# MAIN_CTRL_MMR_MAIN_CTRL_MMR_CFG0_00100000h register map
Vendor: Texas Instruments
Peripheral module from a debugger description file (folder AM275x).
Registers are 32-bit, read-write, reset 0x0 unless marked. A register's access mark holds for its fields unless they carry their own. Offsets are as the file gives them; lines under a group give offsets from that group; [hi:lo] are bit positions; {n}, {i} and the like mark numbered series; 'fields as' and 'values as' point back to an identical list; <NAME> marks a mode.

## main_ctrl_mmr_CFG0 (part 1 of 3)
{0x84F0+4i} MAIN_CTRL_MMRCFG0_ASRC1_TXSYNC{i}_SEL (i=0..3) — Selects the source signal for the ASRC1 TXSYNC{i} frame sync input
  [4:0] ASRC1_TXSYNC{i}_SEL_SYNC_SEL — TXSYNC source signalField values (others are reserved):5'b00000 - McASP0 AFSX Pin Input5'b00001 - McASP1 AFSX Pin Input5'b00010 - McASP2 AFSX Pin Input5'b00011 - McASP3 AFSX Pin Input5'b00100 - McASP4 AFSX Pin Input5'b00101 - '0' - Reserved5'b00110 - '0' - Reserved5'b00111 - '0' - Reserved5'b01000 - McASP0 AFSX Pin Input5'b01001 - McASP1 AFSX Pin Input5'b01010 - McASP2 AFSX Pin Input5'b01011 - McASP3 AFSX Pin Input5'b01100 - McASP4 AFSX Pin Input5'b01101 - '0' - Reserved5'b01110 - '0' - Reserved5'b01111 - '0' - Reserved5'b10000 - AUDIO_EXT_REFCLK0 Pin input5'b10001 - AUDIO_EXT_REFCLK1 Pin input5'b10010 - AUDIO_EXT_REFCLK2 Pin input5'b10011 - '0' - Reserved5'b10100 - ADC0_CLK5'b10101 - MLB_IO_CLK5'b10110 - MAIN_PLL4_HSDIV3_CLKOUT5'b10111 - '0' - Reserved5'b11000 - MCU_EXT_REFCLK0 Pin5'b11001 - EXT_REFCLK1 Pin5'b11010 - CPSW_CPTS_GENF05'b11011 - CPSW_CPTS_GENF15'b11100 - '0' - Reserved5'b11101 - '0' - Reserved5'b11110 - '0' - Reserved5'b11111 - '0' - Reserved Reset Source: mod_g_rst_n
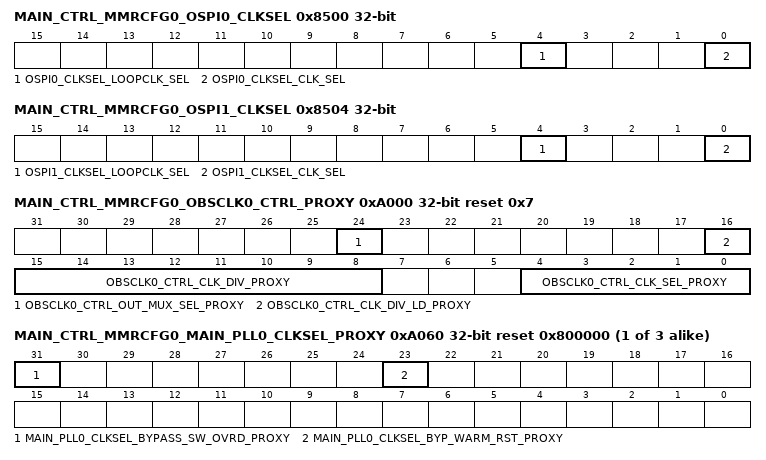
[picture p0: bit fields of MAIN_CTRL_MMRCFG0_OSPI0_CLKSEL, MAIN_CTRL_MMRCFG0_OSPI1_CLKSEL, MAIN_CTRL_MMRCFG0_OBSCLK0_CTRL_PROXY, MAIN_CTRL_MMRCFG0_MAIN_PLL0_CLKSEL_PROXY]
0x8500 MAIN_CTRL_MMRCFG0_OSPI0_CLKSEL — Controls the OSPI loopback clock source
  [4] OSPI0_CLKSEL_LOOPCLK_SEL — OSPI0 Loopback clock sourceField values (others are reserved):1'b0 - Board Level Loopback1'b1 - Internal Loopback Reset Source: mod_g_rst_n
  [0] OSPI0_CLKSEL_CLK_SEL — OSPI0 reference clock selectionField values (others are reserved):1'b0 - MAIN_PLL0_HSDIV1_CLKOUT1'b1 - MAIN_PLL1_HSDIV5_CLKOUT Reset Source: mod_g_rst_n
0x8504 MAIN_CTRL_MMRCFG0_OSPI1_CLKSEL — Controls the OSPI loopback clock source
  [4] OSPI1_CLKSEL_LOOPCLK_SEL — OSPI1 Loopback clock sourceField values (others are reserved):1'b0 - Board Level Loopback1'b1 - Internal Loopback Reset Source: mod_g_rst_n
  [0] OSPI1_CLKSEL_CLK_SEL — OSPI1 reference clock selectionField values (others are reserved):1'b0 - MAIN_PLL0_HSDIV1_CLKOUT1'b1 - MAIN_PLL1_HSDIV5_CLKOUT Reset Source: mod_g_rst_n
0x8510 MAIN_CTRL_MMRCFG0_ADC0_CLKSEL — Controls the functional clock source for the ADC0
  [1:0] ADC0_CLKSEL_CLK_SEL — Selects the sampling clock source for ADC0Field values (others are reserved):2'b00 - HFOSC0_CLKOUT2'b01 - HFOSC1_CLKOUT2'b10 - MAIN_PLL1_HSDIV4_CLKOUT2'b11 - EXT_REFCLK1 (Pin) Reset Source: mod_g_rst_n
0x8580 MAIN_CTRL_MMRCFG0_R5SS0_CLKSEL — Controls Main R5 Subsystem 0 clocking
  [0] R5SS0_CLKSEL_CORE_CLK_SEL — Selects R5SS core and interface clock rateField values (others are reserved):1'b0 - MAIN_PLL14_HSDIV_CLKOUT1'b1 - MAIN_PLL14_HSDIV_CLKOUT / 2 (half speed) Reset Source: mod_g_rst_n
0x8584 MAIN_CTRL_MMRCFG0_R5SS1_CLKSEL — Controls Main R5 Subsystem 1 clocking
  [0] R5SS1_CLKSEL_CORE_CLK_SEL — Selects R5SS core and interface clock rateField values (others are reserved):1'b0 - MAIN_PLL14_HSDIV_CLKOUT1'b1 - MAIN_PLL14_HSDIV_CLKOUT / 2 (half speed) Reset Source: mod_g_rst_n
0x9104 MAIN_CTRL_MMRCFG0_CLAIMREG_P2_R1_READONLY ro
  [31:0] CLAIMREG_P2_R1_READONLY — Claim bits for Partition 2 Reset Source: mod_g_rst_n
0x9110 MAIN_CTRL_MMRCFG0_CLAIMREG_P2_R4_READONLY ro
  [31:0] CLAIMREG_P2_R4_READONLY — Claim bits for Partition 2 Reset Source: mod_g_rst_n
0x9114 MAIN_CTRL_MMRCFG0_CLAIMREG_P2_R5_READONLY ro
  [31:0] CLAIMREG_P2_R5_READONLY — Claim bits for Partition 2 Reset Source: mod_g_rst_n
0x911C MAIN_CTRL_MMRCFG0_CLAIMREG_P2_R7_READONLY ro
  [31:0] CLAIMREG_P2_R7_READONLY — Claim bits for Partition 2 Reset Source: mod_g_rst_n
0x9124 MAIN_CTRL_MMRCFG0_CLAIMREG_P2_R9_READONLY ro
  [31:0] CLAIMREG_P2_R9_READONLY — Claim bits for Partition 2 Reset Source: mod_g_rst_n
0x9128 MAIN_CTRL_MMRCFG0_CLAIMREG_P2_R10_READONLY ro
  [31:0] CLAIMREG_P2_R10_READONLY — Claim bits for Partition 2 Reset Source: mod_g_rst_n
0xA000 MAIN_CTRL_MMRCFG0_OBSCLK0_CTRL_PROXY reset 0x7 — This register controls which internal clock is made observable on the OBSCLK0/1 output pins
  [24] OBSCLK0_CTRL_OUT_MUX_SEL_PROXY — OBSCLK pin output mux selection. PLL4_REFCLK is the direct output from either HFOSC0 or HFOSC1.Field values (others are reserved):1'b0 - Selects the output of the CLK_DIV_OUT clock mux1'b1 - Select PLL4_REFCLK (clk_sel value must be 5'b11111) Reset Source: mod_por_rst_n
  [16] OBSCLK0_CTRL_CLK_DIV_LD_PROXY — Load divisor value from clk_div field, when the bit is toggled from 0 to 1. Field values (others are reserved):1'b0 - READY1'b1 - LOAD Reset Source: mod_por_rst_n
  [15:8] OBSCLK0_CTRL_CLK_DIV_PROXY — OBSCLK0 output divider. Sets divider to divide by clkdiv + 1. Divide by 1 to 256 are supported. After Writing to this field, the clk_div_ld field must be toggled. Reset Source: mod_por_rst_n
  [4:0] OBSCLK0_CTRL_CLK_SEL_PROXY — OBSCLK0 clock source selection.Selects the source of the clock to be divided by the OBSCLK0 divider.Field values (others are reserved):5'b00000 - MAIN_PLL0_HSDIV0_CLKOUT5'b00001 - MAIN_PLL1_HSDIV0_CLKOUT5'b00010 - MAIN_PLL2_HSDIV0_CLKOUT5'b00011 - MAIN_PLL4_HSDIV0_CLKOUT5'b00100 - MAIN_PLL14_HSDIV0_CLKOUT5'b00101 - CLK_12M_RC5'b00110 - HFOSC0_CLKOUT_32K5'b00111 - PLLCTRL_OBSCLK5'b01000 - HFOSC0_CLKOUT5'b01001 - CLK_32K_RC5'b01010 - CPSW0_CPTS_GENF05'b01011 - CPSW0_CPTS_GENF15'b01100 - MCU_PLL0_HSDIV0_CLKOUT5'b01101 - MAIN_PLL15_HSDIV0_CLKOUTundefined - undefinedundefined - undefinedundefined - undefined5'b10000 - MAIN_SYSCLK05'b10001 - DEVICE_CLKOUT_32Kundefined - undefined5'b10011 - C7XV_CLK_DIV4undefined - undefinedundefined - undefined5'b11111 - OFF (Must Select this option when out_mux_sel is set to PLL4_REFCLK) Reset Source: mod_por_rst_n
0xA010 MAIN_CTRL_MMRCFG0_CLKOUT_CTRL_PROXY — Enables and selects clock source of CPSW CLKOUT pin
  [0] CLKOUT_CTRL_CLK_SEL_PROXY — Selects CLKOUT clock sourceField values (others are reserved):1'b0 - MAIN_PLL2_HSDIV1_CLKOUT / 51'b1 - MAIN_PLL2_HSDIV1_CLKOUT / 10 Reset Source: mod_g_rst_n
{0xA060+4i} MAIN_CTRL_MMRCFG0_MAIN_PLL{i}_CLKSEL_PROXY reset 0x800000 (i=0..2) — Controls the clock source for MAIN voltage domain PLL{i}
  [31] MAIN_PLL{i}_CLKSEL_BYPASS_SW_OVRD_PROXY — PLL Bypass warm reset software overrideWhen set, enables software control of exit from bypass mode on a main_reset_z for MAIN PLL{i}. This bit must not be set until after the corresponding byp_warm_rst bit has been cleared or the PLL will immediately enter bypass mode.Field values (others are reserved):1'b0 - Disable1'b1 - Enable Reset Source: sys_por_rst_n
  [23] MAIN_PLL{i}_CLKSEL_BYP_WARM_RST_PROXY — PLL bypass mode after warm reset.This bit is only valid when bypass_sw_ovrd is set to 1'b1 to enable bypass software override.This bit is set (1'b1) when a MAIN warm reset occurs and will keep MAIN PLL{i} in bypass mode after reset exit until cleared by software.Field values (others are reserved):1'b0 - EXIT_BYPASS1'b1 - MAINTAIN_BYPASS Reset Source: main_chip1_rst_n
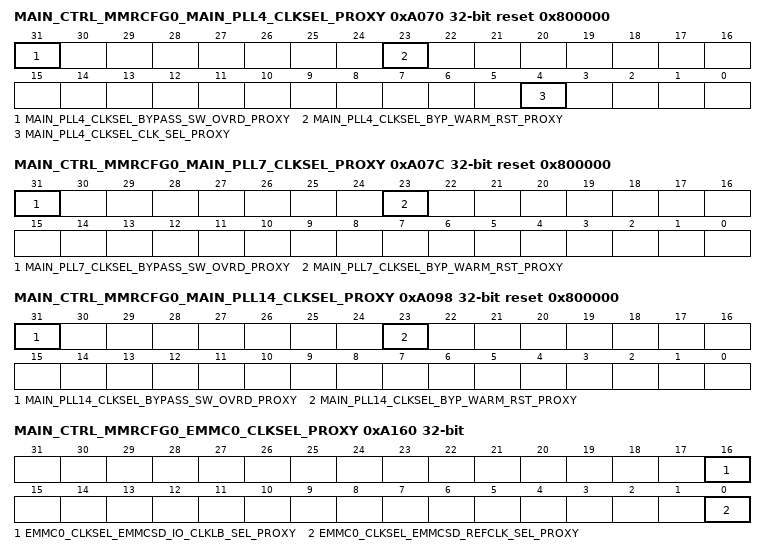
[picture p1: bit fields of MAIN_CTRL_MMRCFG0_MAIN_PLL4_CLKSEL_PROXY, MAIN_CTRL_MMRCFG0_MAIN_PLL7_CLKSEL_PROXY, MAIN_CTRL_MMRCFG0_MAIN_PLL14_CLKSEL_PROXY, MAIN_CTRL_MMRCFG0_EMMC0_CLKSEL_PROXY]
0xA070 MAIN_CTRL_MMRCFG0_MAIN_PLL4_CLKSEL_PROXY reset 0x800000 — Controls the clock source for MAIN voltage domain PLL4
  [31] MAIN_PLL4_CLKSEL_BYPASS_SW_OVRD_PROXY — PLL Bypass warm reset software overrideWhen set, enables software control of exit from bypass mode on a main_reset_z for MAIN PLL4. This bit must not be set until after the corresponding byp_warm_rst bit has been cleared or the PLL will immediately enter bypass mode.Field values (others are reserved):1'b0 - Disable1'b1 - Enable Reset Source: sys_por_rst_n
  [23] MAIN_PLL4_CLKSEL_BYP_WARM_RST_PROXY — PLL bypass mode after warm reset.This bit is only valid when bypass_sw_ovrd is set to 1'b1 to enable bypass software override.This bit is set (1'b1) when a MAIN warm reset occurs and will keep MAIN PLL4 in bypass mode after reset exit until cleared by software.Field values (others are reserved):1'b0 - EXIT_BYPASS1'b1 - MAINTAIN_BYPASS Reset Source: main_chip1_rst_n
  [4] MAIN_PLL4_CLKSEL_CLK_SEL_PROXY — Selects the clock source for MAIN PLL4 1'b0 - Use HFOSC0_CLKOUT 1'b1 - Use HFOSC1_CLKOUT Reset Source: mod_g_rst_n
0xA07C MAIN_CTRL_MMRCFG0_MAIN_PLL7_CLKSEL_PROXY reset 0x800000 — Controls the clock source for MAIN voltage domain PLL7
  [31] MAIN_PLL7_CLKSEL_BYPASS_SW_OVRD_PROXY — PLL Bypass warm reset software overrideWhen set, enables software control of exit from bypass mode on a main_reset_z for MAIN PLL7. This bit must not be set until after the corresponding byp_warm_rst bit has been cleared or the PLL will immediately enter bypass mode.Field values (others are reserved):1'b0 - Disable1'b1 - Enable Reset Source: sys_por_rst_n
  [23] MAIN_PLL7_CLKSEL_BYP_WARM_RST_PROXY — PLL bypass mode after warm reset.This bit is only valid when bypass_sw_ovrd is set to 1'b1 to enable bypass software override.This bit is set (1'b1) when a MAIN warm reset occurs and will keep MAIN PLL7 in bypass mode after reset exit until cleared by software.Field values (others are reserved):1'b0 - EXIT_BYPASS1'b1 - MAINTAIN_BYPASS Reset Source: main_chip1_rst_n
0xA098 MAIN_CTRL_MMRCFG0_MAIN_PLL14_CLKSEL_PROXY reset 0x800000 — Controls the clock source for MAIN voltage domain PLL14
  [31] MAIN_PLL14_CLKSEL_BYPASS_SW_OVRD_PROXY — PLL Bypass warm reset software overrideWhen set, enables software control of exit from bypass mode on a main_reset_z for MAIN PLL14. This bit must not be set until after the corresponding byp_warm_rst bit has been cleared or the PLL will immediately enter bypass mode.Field values (others are reserved):1'b0 - Disable1'b1 - Enable Reset Source: sys_por_rst_n
  [23] MAIN_PLL14_CLKSEL_BYP_WARM_RST_PROXY — PLL bypass mode after warm reset.This bit is only valid when bypass_sw_ovrd is set to 1'b1 to enable bypass software override.This bit is set (1'b1) when a MAIN warm reset occurs and will keep MAIN PLL14 in bypass mode after reset exit until cleared by software.Field values (others are reserved):1'b0 - EXIT_BYPASS1'b1 - MAINTAIN_BYPASS Reset Source: main_chip1_rst_n
0xA140 MAIN_CTRL_MMRCFG0_CPSW_CLKSEL_PROXY reset 0x7 — Selects the CP Switch clock sources
  [2:0] CPSW_CLKSEL_CPTS_CLKSEL_PROXY — Selects the clock source for the CPSW Ethernet switch Common Platform Time Stamp moduleField values (others are reserved):3'b000 - MAIN_PLL2_HSDIV5_CLKOUT3'b001 - MAIN_PLL0_HSDIV6_CLKOUT3'b010 - CP_GEMAC_CPTS0_RFT_CLK (Pin)3'b011 - Reserved3'b100 - MCU_EXT_REFCLK0 (Pin)3'b101 - EXT_REFCLK1 (Pin)3'b110 - SERDES0_IP1_LN0_TXMCLKundefined - undefined3'b111 - MAIN_SYSCLK0 Reset Source: mod_por_rst_n
0xA160 MAIN_CTRL_MMRCFG0_EMMC0_CLKSEL_PROXY — Selects the functional clock source for 8-bit eMMC0
  [16] EMMC0_CLKSEL_EMMCSD_IO_CLKLB_SEL_PROXY — Selects IO Pad Loopback for the MMC ModuleField values (others are reserved):1'b0 - Loopback from Unbonded Pad MMCSD0_CLKLB1'b1 - Loopback from IO Pin MMCSD0_CLK Reset Source: mod_g_rst_n
  [0] EMMC0_CLKSEL_EMMCSD_REFCLK_SEL_PROXY — Selects the functional clock for the MMC ModuleField values (others are reserved):1'b0 - MAIN_PLL0_HSDIV5_CLKOUT1'b1 - MAIN_PLL2_HSDIV2_CLKOUT Reset Source: mod_g_rst_n
{0xA1B0+4i} MAIN_CTRL_MMRCFG0_TIMER{i}_CLKSEL_PROXY (i=0..15) — Timer{i} functional clock selection control
  [3:0] TIMER{i}_CLKSEL_CLK_SEL_PROXY — Timer functional clock input select control.Field values (others are reserved):4'b0000 - HFOSC0_CLKOUT4'b0001 - DEVICE_CLKOUT_32K4'b0010 - MAIN_PLL0_HSDIV7_CLKOUT4'b0011 - CLK_12M_RC4'b0100 - MCU_EXT_REFCLK0 (Pin)4'b0101 - EXT_REFCLK1 (Pin)4'b0110 - Reserved4'b0111 - CP_GEMAC_CPTS0_RFT_CLK (Pin)4'b1000 - MAIN_PLL1_HSDIV3_CLKOUT4'b1001 - MAIN_PLL2_HSDIV6_CLKOUT4'b1010 - CPSW0_CPTS_GENF04'b1011 - CPSW0_CPTS_GENF14'b1100 - Reserved Reset Source: sys_por_rst_n
{0xA200+4i} MAIN_CTRL_MMRCFG0_SPI{i}_CLKSEL_PROXY (i=0..4) — SPI{i} clock control
  [16] SPI{i}_CLKSEL_MSTR_LB_CLKSEL_PROXY — Controller mode receive capture clock loopback selectionField values (others are reserved):1'b0 - INTERNAL_LOOPBACK1'b1 - EXTERNAL_LOOPBACK Reset Source: mod_g_rst_n
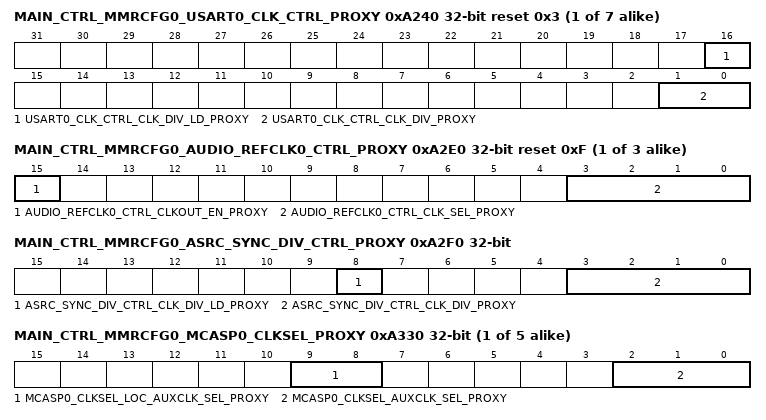
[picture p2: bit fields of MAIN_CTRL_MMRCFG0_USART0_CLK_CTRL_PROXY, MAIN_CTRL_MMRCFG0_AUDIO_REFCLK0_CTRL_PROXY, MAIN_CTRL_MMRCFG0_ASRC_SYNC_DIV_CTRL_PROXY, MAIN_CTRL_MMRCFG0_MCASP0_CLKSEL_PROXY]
{0xA240+4i} MAIN_CTRL_MMRCFG0_USART{i}_CLK_CTRL_PROXY reset 0x3 (i=0..6) — Selects the clock divider of the USART{i} functional clock
  [16] USART{i}_CLK_CTRL_CLK_DIV_LD_PROXY — Load the output divider valueWriting 1 to this bit will generate a load pulse to load the USART{i} clock programmable divider value. This bit can be cleared but must not be set in the same write cycle in which the clk_div value is changed. Field values (others are reserved):1'b0 - READY1'b1 - LOAD Reset Source: mod_g_rst_n
  [1:0] USART{i}_CLK_CTRL_CLK_DIV_PROXY — Selects the clock divider value. Supports divide values of 1 to 4 Default is /4. To load the new divider value the clk_div_ld bit must be cleared and then set to 1.Field values (others are reserved):2'b00 - Divide by 12'b01 - Divide by 22'b10 - Divide by 32'b11 - Divide by 4 Reset Source: mod_g_rst_n
{0xA280+4i} MAIN_CTRL_MMRCFG0_USART{i}_CLKSEL_PROXY (i=0..6) — Selects the clock source for USART{i} functional clock
  [0] USART{i}_CLKSEL_CLK_SEL_PROXY — Selects the clock source for UART{i}:Field values (others are reserved):1'b0 - MAIN_PLL1_HSDIV0_CLKOUT Divider Output (See USART{i}_CLK_CTRL)1'b1 - MAIN_PLL1_HSDIV1_CLKOUT Reset Source: mod_g_rst_n
0xA2B0 MAIN_CTRL_MMRCFG0_ATL_CLKSEL_PROXY — Selects the source of ATL PCLK which drives ATL Measurement and Adjustment Logic
  [2:0] ATL_CLKSEL_PCLK_SEL_PROXY — Selects the PCLK clock sourceField values (others are reserved):3'b000 - MAIN_PLL2_HSDIV8_CLKOUT3'b001 - MAIN_PLL1_HSDIV6_CLKOUT3'b010 - MAIN_PLL2_HSDIV0_CLKOUT3'b011 - MAIN_PLL4_HSDIV1_CLKOUT3'b100 - MAIN_PLL0_HSDIV7_CLKOUT3'b101 - MCU_EXT_REFCLK0 (Pin)3'b110 - EXT_REFCLK1 (Pin) Reset Source: mod_g_rst_n
{0xA2C0+4i} MAIN_CTRL_MMRCFG0_ATL_BWS{i}_SEL_PROXY (i=0..3) — Selects the word clock for the ATL channel{i} Baseband Stream
  [3:0] ATL_BWS{i}_SEL_WD_SEL_PROXY — BWS source signalField values (others are reserved):4'b0000 - MCASP0_AFSR_IN4'b0001 - MCASP1_AFSR_IN4'b0010 - MCASP2_AFSR_IN4'b0011 - MCASP3_AFSR_IN4'b0100 - MCASP4_AFSR_IN4'b0101 - MCASP0_AFSX_IN4'b0110 - MCASP1_AFSX_IN4'b0111 - MCASP2_AFSX_IN4'b1000 - MCASP3_AFSX_IN4'b1001 - MCASP4_AFSX_IN4'b1010 - AUDIO_EXT_REFCLK0_IN4'b1011 - AUDIO_EXT_REFCLK1_IN4'b1100 - AUDIO_EXT_REFCLK2_IN Reset Source: mod_g_rst_n
{0xA2D0+4i} MAIN_CTRL_MMRCFG0_ATL_AWS{i}_SEL_PROXY (i=0..3) — Selects the word clock for the ATL channel{i} Audio Stream
  [3:0] ATL_AWS{i}_SEL_WD_SEL_PROXY — AWS source signalField values (others are reserved):4'b0000 - MCASP0_AFSX_IN4'b0001 - MCASP1_AFSX_IN4'b0010 - MCASP2_AFSX_IN4'b0011 - MCASP3_AFSX_IN4'b0100 - MCASP4_AFSX_IN4'b0101 - MCASP0_AFSX_IN4'b0110 - MCASP1_AFSX_IN4'b0111 - MCASP2_AFSX_IN4'b1000 - MCASP3_AFSX_IN4'b1001 - MCASP4_AFSX_IN4'b1010 - AUDIO_EXT_REFCLK0_IN4'b1011 - AUDIO_EXT_REFCLK1_IN4'b1100 - AUDIO_EXT_REFCLK2_IN Reset Source: mod_g_rst_n
{0xA2E0+4i} MAIN_CTRL_MMRCFG0_AUDIO_REFCLK{i}_CTRL_PROXY reset 0xF (i=0..2) — Selects the clock source for the AUDIO_EXT_REFCLK0 output, and direction.
  [15] AUDIO_REFCLK{i}_CTRL_CLKOUT_EN_PROXY — AUDIO_REFCLK {i} output enableField values (others are reserved):1'b0 - INPUT1'b1 - OUTPUT Reset Source: mod_g_rst_n
  [3:0] AUDIO_REFCLK{i}_CTRL_CLK_SEL_PROXY — Selects the source of AUDIO_REFCLK{i}Field values (others are reserved):4'b0000 - MCASP0_AHCLKR4'b0001 - MCASP1_AHCLKR4'b0010 - MCASP2_AHCLKR4'b0011 - MCASP3_AHCLKR4'b0100 - MCASP4_AHCLKR4'b0101 - MCASP0_AHCLKX4'b0110 - MCASP1_AHCLKX4'b0111 - MCASP2_AHCLKX4'b1000 - MCASP3_AHCLKX4'b1001 - MCASP4_AHCLKX4'b1010 - ATCLK04'b1011 - ATCLK14'b1100 - ATCLK24'b1101 - ATCLK34'b1110 - MAIN_PLL1_HSDIV6_CLKOUTundefined - undefined4'b1111 - MAIN_PLL4_HSDIV0_CLKOUT Reset Source: mod_g_rst_n
0xA2F0 MAIN_CTRL_MMRCFG0_ASRC_SYNC_DIV_CTRL_PROXY — Selects additional divide value for the MAIN_PLL4 clock source to the ASRC RXSYNC and TXSYNC selection muxes
  [8] ASRC_SYNC_DIV_CTRL_CLK_DIV_LD_PROXY — Load the divider valueWriting 1 to this bit will generate a load pulse to load the clk_div divider value. This bit can be cleared but must not be set in the same write cycle in which the clk_div value is changed. Field values (others are reserved):1'b0 - READY1'b1 - LOAD Reset Source: mod_g_rst_n
  [3:0] ASRC_SYNC_DIV_CTRL_CLK_DIV_PROXY — ASRC Sync divider valueDivides MAIN_PLL4_HSDIV_CLKOUT3 by clkdiv+1. Supports divide by 1 to 16 (default to 1). To load the new divider value the clk_div_ld bit must be cleared and then set to 1. Reset Source: mod_g_rst_n
{0xA330+4i} MAIN_CTRL_MMRCFG0_MCASP{i}_CLKSEL_PROXY (i=0..4) — Selects the functional clock source for McASP{i}
  [9:8] MCASP{i}_CLKSEL_LOC_AUXCLK_SEL_PROXY — Selects the local clock source to use for McASP{i} AUXCLKField values (others are reserved):2'b00 - PLL4_REF_CLK (as selected by MAIN_PLL4_CLKSEL_clk_sel)2'b01 - PLL4_REF_CLK / 2 (as selected by MAIN_PLL4_CLKSEL_clk_sel)2'b10 - MAIN_PLL4_HSDIV0_CLKOUT Reset Source: mod_g_rst_n
  [2:0] MCASP{i}_CLKSEL_AUXCLK_SEL_PROXY — Selects the system AUXCLK input source for McASP{i}Field values (others are reserved):3'b000 - MAIN_PLL2_HSDIV8_CLKOUT3'b001 - MAIN_PLL1_HSDIV6_CLKOUT3'b011 - AUDIO_EXT_REFCLK0 (Pin)3'b100 - AUDIO_EXT_REFCLK1 (Pin)3'b101 - AUDIO_EXT_REFCLK2 (Pin)3'b110 - ATCLK03'b111 - ATCLK1 Reset Source: mod_g_rst_n
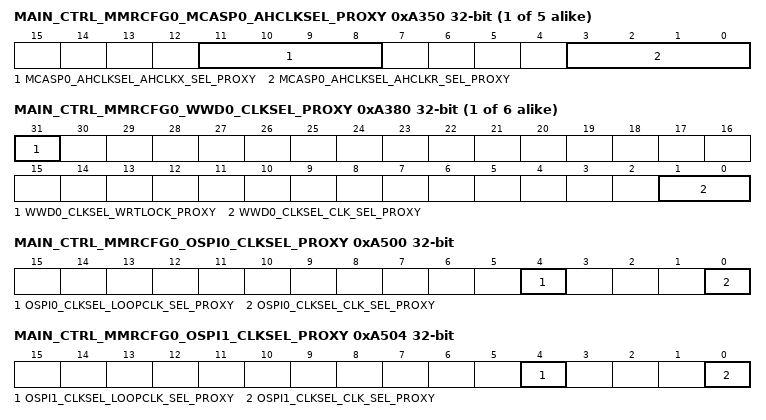
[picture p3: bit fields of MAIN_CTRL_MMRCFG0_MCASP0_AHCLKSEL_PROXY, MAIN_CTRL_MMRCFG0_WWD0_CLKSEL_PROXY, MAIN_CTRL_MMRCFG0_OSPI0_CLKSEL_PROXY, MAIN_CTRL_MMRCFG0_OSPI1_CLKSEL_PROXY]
{0xA350+4i} MAIN_CTRL_MMRCFG0_MCASP{i}_AHCLKSEL_PROXY (i=0..4) — Selects the AHCLKX and AHCLKR clock source for McASP{i}
  [11:8] MCASP{i}_AHCLKSEL_AHCLKX_SEL_PROXY — Selects the AHCLKX input source for McASP{i}Field values (others are reserved):4'b0000 - EXT_REFCLK1 (Pin)4'b0001 - HFOSC0_CLKOUT4'b0010 - AUDIO_EXT_REFCLK0 (Pin)4'b0011 - AUDIO_EXT_REFCLK1 (Pin)4'b0100 - AUDIO_EXT_REFCLK2 (Pin)undefined - undefined4'b0110 - MLB_IO_CLKundefined - undefined4'b1000 - ATCLK04'b1001 - ATCLK14'b1010 - ATCLK24'b1011 - ATCLK34'b1100 - CPSW CPTS GENF04'b1101 - CPSW CPTS GENF0 Reset Source: mod_g_rst_n
  [3:0] MCASP{i}_AHCLKSEL_AHCLKR_SEL_PROXY — Selects the AHCLKR input source for McASP{i}Field values (others are reserved):4'b0000 - EXT_REFCLK1 (Pin)4'b0001 - HFOSC0_CLKOUT4'b0010 - AUDIO_EXT_REFCLK0 (Pin)4'b0011 - AUDIO_EXT_REFCLK1 (Pin)4'b0100 - AUDIO_EXT_REFCLK2 (Pin)undefined - undefined4'b0110 - MLB_IO_CLKundefined - undefined4'b1000 - ATCLK04'b1001 - ATCLK14'b1010 - ATCLK24'b1011 - ATCLK34'b1100 - CPSW CPTS GENF04'b1101 - CPSW CPTS GENF0 Reset Source: mod_g_rst_n
{0xA380+4i} MAIN_CTRL_MMRCFG0_WWD{i}_CLKSEL_PROXY (i=0..5) — Windowed Watchdog WWD{i} functional clock selection control
  [31] WWD{i}_CLKSEL_WRTLOCK_PROXY — When set, locks WWD{i}_CLKSEL from further writes until the next module reset.Field values (others are reserved):1'b0 - UNLOCKED1'b1 - LOCKED Reset Source: mod_g_rst_n
  [1:0] WWD{i}_CLKSEL_CLK_SEL_PROXY — Windowed watchdog timer functional clock input select mux controlField values (others are reserved):2'b00 - HFOSC0_CLKOUT2'b01 - DEVICE_CLKOUT_32K2'b10 - CLK_12M_RC2'b11 - CLK_32K Reset Source: mod_g_rst_n
{0xA3E0+4i} MAIN_CTRL_MMRCFG0_MCASP{i}_GF_CLK_SEL_PROXY (i=0..4) — Performs glitchfree selection of the McASP{i} functional clock
  [16] MCASP{i}_GF_CLK_SEL_AUXCLK_GF_SEL_PROXY — Provides glitch-free switching between the local and system AUXCLK source for McASP{i} based on MCASP{i}_CLKSEL loc_auxclk_sel and auxclk_sel settings.Field values (others are reserved):1'b0 - Use local AUXCLK source (as selected by loc_auxclk_sel bitfield)1'b1 - Use system AUXCLK source (as selected by auxsel_sel bitfield) Reset Source: mod_g_rst_n
{0xA480+4i} MAIN_CTRL_MMRCFG0_MCAN{i}_CLKSEL_PROXY (i=0..4) — Controls the functional clock source for MCAN{i}
  [1:0] MCAN{i}_CLKSEL_CLK_SEL_PROXY — MCAN functional clock selectionField values (others are reserved):2'b00 - MAIN_PLL0_HSDIV4_CLKOUT2'b01 - MCU_EXT_REFCLK0 (Pin)2'b10 - EXT_REFCLK1 (Pin)2'b11 - HFOSC0_CLKOUT Reset Source: sys_por_rst_n
{0xA4C0+4i} MAIN_CTRL_MMRCFG0_ASRC0_RXSYNC{i}_SEL_PROXY (i=0..3) — Selects the source signal for the ASRC0 RXSYNC{i} frame sync input
  [4:0] ASRC0_RXSYNC{i}_SEL_SYNC_SEL_PROXY — RXSYNC source signalField values (others are reserved):5'b00000 - McASP0 AFSR Pin Input5'b00001 - McASP1 AFSR Pin Input5'b00010 - McASP2 AFSR Pin Input5'b00011 - McASP3 AFSR Pin Input5'b00100 - McASP4 AFSR Pin Input5'b00101 - '0' - Reserved5'b00110 - '0' - Reserved5'b00111 - '0' - Reserved5'b01000 - McASP0 AFSX Pin Input5'b01001 - McASP1 AFSX Pin Input5'b01010 - McASP2 AFSX Pin Input5'b01011 - McASP3 AFSX Pin Input5'b01100 - McASP4 AFSX Pin Input5'b01101 - '0' - Reserved5'b01110 - '0' - Reserved5'b01111 - '0' - Reserved5'b10000 - AUDIO_EXT_REFCLK0 Pin input5'b10001 - AUDIO_EXT_REFCLK1 Pin input5'b10010 - AUDIO_EXT_REFCLK2 Pin input5'b10011 - '0' - Reserved5'b10100 - ADC0_CLK5'b10101 - MLB_IO_CLK5'b10110 - MAIN_PLL4_HSDIV3_CLKOUT5'b10111 - '0' - Reserved5'b11000 - MCU_EXT_REFCLK0 Pin5'b11001 - EXT_REFCLK1 Pin5'b11010 - CPSW_CPTS_GENF05'b11011 - CPSW_CPTS_GENF15'b11100 - '0' - Reserved5'b11101 - '0' - Reserved5'b11110 - '0' - Reserved5'b11111 - '0' - Reserved Reset Source: mod_g_rst_n
{0xA4D0+4i} MAIN_CTRL_MMRCFG0_ASRC1_RXSYNC{i}_SEL_PROXY (i=0..3) — Selects the source signal for the ASRC1 RXSYNC{i} frame sync input
  [4:0] ASRC1_RXSYNC{i}_SEL_SYNC_SEL_PROXY — RXSYNC source signalField values (others are reserved):5'b00000 - McASP0 AFSR Pin Input5'b00001 - McASP1 AFSR Pin Input5'b00010 - McASP2 AFSR Pin Input5'b00011 - McASP3 AFSR Pin Input5'b00100 - McASP4 AFSR Pin Input5'b00101 - '0' - Reserved5'b00110 - '0' - Reserved5'b00111 - '0' - Reserved5'b01000 - McASP0 AFSX Pin Input5'b01001 - McASP1 AFSX Pin Input5'b01010 - McASP2 AFSX Pin Input5'b01011 - McASP3 AFSX Pin Input5'b01100 - McASP4 AFSX Pin Input5'b01101 - '0' - Reserved5'b01110 - '0' - Reserved5'b01111 - '0' - Reserved5'b10000 - AUDIO_EXT_REFCLK0 Pin input5'b10001 - AUDIO_EXT_REFCLK1 Pin input5'b10010 - AUDIO_EXT_REFCLK2 Pin input5'b10011 - '0' - Reserved5'b10100 - ADC0_CLK5'b10101 - MLB_IO_CLK5'b10110 - MAIN_PLL4_HSDIV3_CLKOUT5'b10111 - '0' - Reserved5'b11000 - MCU_EXT_REFCLK0 Pin5'b11001 - EXT_REFCLK1 Pin5'b11010 - CPSW_CPTS_GENF05'b11011 - CPSW_CPTS_GENF15'b11100 - '0' - Reserved5'b11101 - '0' - Reserved5'b11110 - '0' - Reserved5'b11111 - '0' - Reserved Reset Source: mod_g_rst_n
{0xA4E0+4i} MAIN_CTRL_MMRCFG0_ASRC0_TXSYNC{i}_SEL_PROXY (i=0..3) — Selects the source signal for the ASRC0 TXSYNC{i} frame sync input
  [4:0] ASRC0_TXSYNC{i}_SEL_SYNC_SEL_PROXY — TXSYNC source signalField values (others are reserved):5'b00000 - McASP0 AFSX Pin Input5'b00001 - McASP1 AFSX Pin Input5'b00010 - McASP2 AFSX Pin Input5'b00011 - McASP3 AFSX Pin Input5'b00100 - McASP4 AFSX Pin Input5'b00101 - '0' - Reserved5'b00110 - '0' - Reserved5'b00111 - '0' - Reserved5'b01000 - McASP0 AFSX Pin Input5'b01001 - McASP1 AFSX Pin Input5'b01010 - McASP2 AFSX Pin Input5'b01011 - McASP3 AFSX Pin Input5'b01100 - McASP4 AFSX Pin Input5'b01101 - '0' - Reserved5'b01110 - '0' - Reserved5'b01111 - '0' - Reserved5'b10000 - AUDIO_EXT_REFCLK0 Pin input5'b10001 - AUDIO_EXT_REFCLK1 Pin input5'b10010 - AUDIO_EXT_REFCLK2 Pin input5'b10011 - '0' - Reserved5'b10100 - ADC0_CLK5'b10101 - MLB_IO_CLK5'b10110 - MAIN_PLL4_HSDIV3_CLKOUT5'b10111 - '0' - Reserved5'b11000 - MCU_EXT_REFCLK0 Pin5'b11001 - EXT_REFCLK1 Pin5'b11010 - CPSW_CPTS_GENF05'b11011 - CPSW_CPTS_GENF15'b11100 - '0' - Reserved5'b11101 - '0' - Reserved5'b11110 - '0' - Reserved5'b11111 - '0' - Reserved Reset Source: mod_g_rst_n
{0xA4F0+4i} MAIN_CTRL_MMRCFG0_ASRC1_TXSYNC{i}_SEL_PROXY (i=0..3) — Selects the source signal for the ASRC1 TXSYNC{i} frame sync input
  [4:0] ASRC1_TXSYNC{i}_SEL_SYNC_SEL_PROXY — TXSYNC source signalField values (others are reserved):5'b00000 - McASP0 AFSX Pin Input5'b00001 - McASP1 AFSX Pin Input5'b00010 - McASP2 AFSX Pin Input5'b00011 - McASP3 AFSX Pin Input5'b00100 - McASP4 AFSX Pin Input5'b00101 - '0' - Reserved5'b00110 - '0' - Reserved5'b00111 - '0' - Reserved5'b01000 - McASP0 AFSX Pin Input5'b01001 - McASP1 AFSX Pin Input5'b01010 - McASP2 AFSX Pin Input5'b01011 - McASP3 AFSX Pin Input5'b01100 - McASP4 AFSX Pin Input5'b01101 - '0' - Reserved5'b01110 - '0' - Reserved5'b01111 - '0' - Reserved5'b10000 - AUDIO_EXT_REFCLK0 Pin input5'b10001 - AUDIO_EXT_REFCLK1 Pin input5'b10010 - AUDIO_EXT_REFCLK2 Pin input5'b10011 - '0' - Reserved5'b10100 - ADC0_CLK5'b10101 - MLB_IO_CLK5'b10110 - MAIN_PLL4_HSDIV3_CLKOUT5'b10111 - '0' - Reserved5'b11000 - MCU_EXT_REFCLK0 Pin5'b11001 - EXT_REFCLK1 Pin5'b11010 - CPSW_CPTS_GENF05'b11011 - CPSW_CPTS_GENF15'b11100 - '0' - Reserved5'b11101 - '0' - Reserved5'b11110 - '0' - Reserved5'b11111 - '0' - Reserved Reset Source: mod_g_rst_n
0xA500 MAIN_CTRL_MMRCFG0_OSPI0_CLKSEL_PROXY — Controls the OSPI loopback clock source
  [4] OSPI0_CLKSEL_LOOPCLK_SEL_PROXY — OSPI0 Loopback clock sourceField values (others are reserved):1'b0 - Board Level Loopback1'b1 - Internal Loopback Reset Source: mod_g_rst_n
  [0] OSPI0_CLKSEL_CLK_SEL_PROXY — OSPI0 reference clock selectionField values (others are reserved):1'b0 - MAIN_PLL0_HSDIV1_CLKOUT1'b1 - MAIN_PLL1_HSDIV5_CLKOUT Reset Source: mod_g_rst_n
0xA504 MAIN_CTRL_MMRCFG0_OSPI1_CLKSEL_PROXY — Controls the OSPI loopback clock source
  [4] OSPI1_CLKSEL_LOOPCLK_SEL_PROXY — OSPI1 Loopback clock sourceField values (others are reserved):1'b0 - Board Level Loopback1'b1 - Internal Loopback Reset Source: mod_g_rst_n
  [0] OSPI1_CLKSEL_CLK_SEL_PROXY — OSPI1 reference clock selectionField values (others are reserved):1'b0 - MAIN_PLL0_HSDIV1_CLKOUT1'b1 - MAIN_PLL1_HSDIV5_CLKOUT Reset Source: mod_g_rst_n
0xA510 MAIN_CTRL_MMRCFG0_ADC0_CLKSEL_PROXY — Controls the functional clock source for the ADC0
  [1:0] ADC0_CLKSEL_CLK_SEL_PROXY — Selects the sampling clock source for ADC0Field values (others are reserved):2'b00 - HFOSC0_CLKOUT2'b01 - HFOSC1_CLKOUT2'b10 - MAIN_PLL1_HSDIV4_CLKOUT2'b11 - EXT_REFCLK1 (Pin) Reset Source: mod_g_rst_n
0xA580 MAIN_CTRL_MMRCFG0_R5SS0_CLKSEL_PROXY — Controls Main R5 Subsystem 0 clocking
  [0] R5SS0_CLKSEL_CORE_CLK_SEL_PROXY — Selects R5SS core and interface clock rateField values (others are reserved):1'b0 - MAIN_PLL14_HSDIV_CLKOUT1'b1 - MAIN_PLL14_HSDIV_CLKOUT / 2 (half speed) Reset Source: mod_g_rst_n
0xA584 MAIN_CTRL_MMRCFG0_R5SS1_CLKSEL_PROXY — Controls Main R5 Subsystem 1 clocking
  [0] R5SS1_CLKSEL_CORE_CLK_SEL_PROXY — Selects R5SS core and interface clock rateField values (others are reserved):1'b0 - MAIN_PLL14_HSDIV_CLKOUT1'b1 - MAIN_PLL14_HSDIV_CLKOUT / 2 (half speed) Reset Source: mod_g_rst_n
{0xB100+4i} MAIN_CTRL_MMRCFG0_CLAIMREG_P2_R{i} (i=0..11)
  [31:0] CLAIMREG_P2_R{i} — Claim bits for Partition 2 Reset Source: mod_g_rst_n
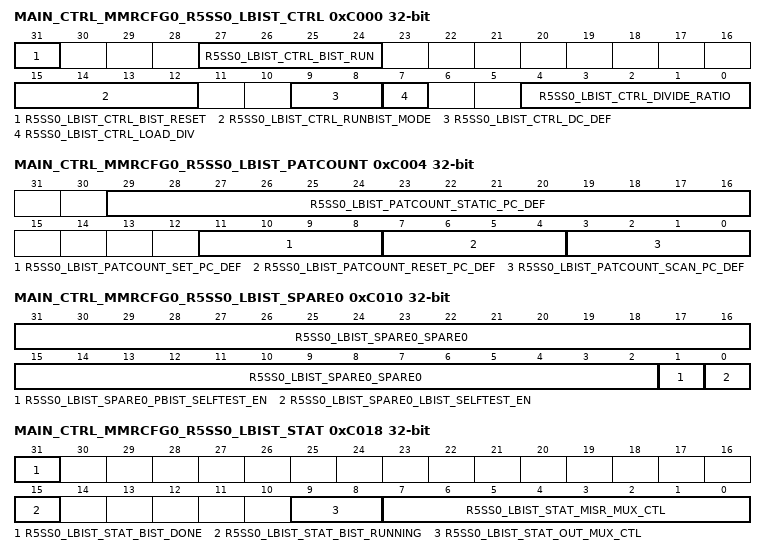
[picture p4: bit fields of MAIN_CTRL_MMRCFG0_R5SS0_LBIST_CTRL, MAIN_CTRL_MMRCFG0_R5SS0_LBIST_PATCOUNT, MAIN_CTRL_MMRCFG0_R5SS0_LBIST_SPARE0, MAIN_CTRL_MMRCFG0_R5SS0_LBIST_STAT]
0xC000 MAIN_CTRL_MMRCFG0_R5SS0_LBIST_CTRL — Configures and enables LBIST operation
  [31] R5SS0_LBIST_CTRL_BIST_RESET — Reset LBIST macro Reset Source: mod_g_rst_n
  [27:24] R5SS0_LBIST_CTRL_BIST_RUN — Starts LBIST if all bits are 1 Reset Source: mod_g_rst_n
  [15:12] R5SS0_LBIST_CTRL_RUNBIST_MODE — Runbist mode enable if all bits are 1 Reset Source: mod_g_rst_n
  [9:8] R5SS0_LBIST_CTRL_DC_DEF — Clock delay after scan_enable switching Reset Source: mod_g_rst_n
  [7] R5SS0_LBIST_CTRL_LOAD_DIV — Loads LBIST clock divide ratio on transition from 0 to 1 Reset Source: mod_g_rst_n
  [4:0] R5SS0_LBIST_CTRL_DIVIDE_RATIO — LBIST clock divide ratio Reset Source: mod_g_rst_n
0xC004 MAIN_CTRL_MMRCFG0_R5SS0_LBIST_PATCOUNT — Specifies the number of LBIST patterns to run
  [29:16] R5SS0_LBIST_PATCOUNT_STATIC_PC_DEF — Number of stuck-at patterns to run Reset Source: mod_g_rst_n
  [11:8] R5SS0_LBIST_PATCOUNT_SET_PC_DEF — Number of set patterns to run Reset Source: mod_g_rst_n
  [7:4] R5SS0_LBIST_PATCOUNT_RESET_PC_DEF — Number of reset patterns to run Reset Source: mod_g_rst_n
  [3:0] R5SS0_LBIST_PATCOUNT_SCAN_PC_DEF — Number of chain test patterns to run Reset Source: mod_g_rst_n
0xC008 MAIN_CTRL_MMRCFG0_R5SS0_LBIST_SEED0 — Specifies the 32 LSBs of the PRPG seed
  [31:0] R5SS0_LBIST_SEED0_PRPG_DEF — Initial seed for PRPG (bits 31:0) Reset Source: mod_g_rst_n
0xC00C MAIN_CTRL_MMRCFG0_R5SS0_LBIST_SEED1 — Specifies the 21 MSBs of the PRPG seed
  [20:0] R5SS0_LBIST_SEED1_PRPG_DEF — Initial seed for PRPG (bits 52:32) Reset Source: mod_g_rst_n
0xC010 MAIN_CTRL_MMRCFG0_R5SS0_LBIST_SPARE0 — Spare LBIST control bits
  [31:2] R5SS0_LBIST_SPARE0_SPARE0 — LBIST spare bits Reset Source: mod_g_rst_n
  [1] R5SS0_LBIST_SPARE0_PBIST_SELFTEST_EN — PBIST isolation control Reset Source: mod_g_rst_n
  [0] R5SS0_LBIST_SPARE0_LBIST_SELFTEST_EN — LBIST isolation control Reset Source: mod_g_rst_n
0xC014 MAIN_CTRL_MMRCFG0_R5SS0_LBIST_SPARE1 — Spare LBIST control bits
  [31:0] R5SS0_LBIST_SPARE1_SPARE1 — LBIST spare bits Reset Source: mod_g_rst_n
0xC018 MAIN_CTRL_MMRCFG0_R5SS0_LBIST_STAT access per field — Indicates LBIST status and provides MISR selection control
  [31] R5SS0_LBIST_STAT_BIST_DONE ro — LBIST is done Reset Source: mod_g_rst_n
  [15] R5SS0_LBIST_STAT_BIST_RUNNING ro — LBIST is running Reset Source: mod_g_rst_n
  [9:8] R5SS0_LBIST_STAT_OUT_MUX_CTL rw — Selects source of LBIST output 00 - LBIST IP PID value 01 - LBIST CTRL ID value 1x - MISR value Reset Source: mod_g_rst_n
  [7:0] R5SS0_LBIST_STAT_MISR_MUX_CTL rw — Selects block of 32 MISR bits to read. A value of 0 selects a compacted 32-bit version of the full MISR. A value of 1-32 select a 32-bit segment of the MISR. Reset Source: mod_g_rst_n
0xC01C MAIN_CTRL_MMRCFG0_R5SS0_LBIST_MISR ro — Contains LBIST MISR output value
  [31:0] R5SS0_LBIST_MISR_MISR_RESULT — 32-bits of MISR value selected by misr_mux_ctl Reset Source: mod_g_rst_n
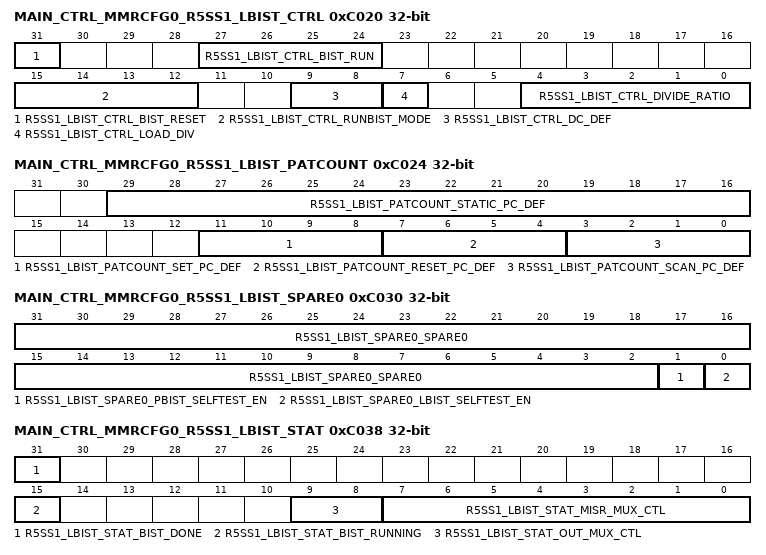
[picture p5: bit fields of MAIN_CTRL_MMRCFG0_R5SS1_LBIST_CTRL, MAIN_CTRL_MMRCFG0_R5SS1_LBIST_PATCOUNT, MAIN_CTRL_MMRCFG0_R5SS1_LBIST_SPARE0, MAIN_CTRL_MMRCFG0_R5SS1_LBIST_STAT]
0xC020 MAIN_CTRL_MMRCFG0_R5SS1_LBIST_CTRL — Configures and enables LBIST operation
  [31] R5SS1_LBIST_CTRL_BIST_RESET — Reset LBIST macro Reset Source: mod_g_rst_n
  [27:24] R5SS1_LBIST_CTRL_BIST_RUN — Starts LBIST if all bits are 1 Reset Source: mod_g_rst_n
  [15:12] R5SS1_LBIST_CTRL_RUNBIST_MODE — Runbist mode enable if all bits are 1 Reset Source: mod_g_rst_n
  [9:8] R5SS1_LBIST_CTRL_DC_DEF — Clock delay after scan_enable switching Reset Source: mod_g_rst_n
  [7] R5SS1_LBIST_CTRL_LOAD_DIV — Loads LBIST clock divide ratio on transition from 0 to 1 Reset Source: mod_g_rst_n
  [4:0] R5SS1_LBIST_CTRL_DIVIDE_RATIO — LBIST clock divide ratio Reset Source: mod_g_rst_n
0xC024 MAIN_CTRL_MMRCFG0_R5SS1_LBIST_PATCOUNT — Specifies the number of LBIST patterns to run
  [29:16] R5SS1_LBIST_PATCOUNT_STATIC_PC_DEF — Number of stuck-at patterns to run Reset Source: mod_g_rst_n
  [11:8] R5SS1_LBIST_PATCOUNT_SET_PC_DEF — Number of set patterns to run Reset Source: mod_g_rst_n
  [7:4] R5SS1_LBIST_PATCOUNT_RESET_PC_DEF — Number of reset patterns to run Reset Source: mod_g_rst_n
  [3:0] R5SS1_LBIST_PATCOUNT_SCAN_PC_DEF — Number of chain test patterns to run Reset Source: mod_g_rst_n
0xC028 MAIN_CTRL_MMRCFG0_R5SS1_LBIST_SEED0 — Specifies the 32 LSBs of the PRPG seed
  [31:0] R5SS1_LBIST_SEED0_PRPG_DEF — Initial seed for PRPG (bits 31:0) Reset Source: mod_g_rst_n
0xC02C MAIN_CTRL_MMRCFG0_R5SS1_LBIST_SEED1 — Specifies the 21 MSBs of the PRPG seed
  [20:0] R5SS1_LBIST_SEED1_PRPG_DEF — Initial seed for PRPG (bits 52:32) Reset Source: mod_g_rst_n
0xC030 MAIN_CTRL_MMRCFG0_R5SS1_LBIST_SPARE0 — Spare LBIST control bits
  [31:2] R5SS1_LBIST_SPARE0_SPARE0 — LBIST spare bits Reset Source: mod_g_rst_n
  [1] R5SS1_LBIST_SPARE0_PBIST_SELFTEST_EN — PBIST isolation control Reset Source: mod_g_rst_n
  [0] R5SS1_LBIST_SPARE0_LBIST_SELFTEST_EN — LBIST isolation control Reset Source: mod_g_rst_n
0xC034 MAIN_CTRL_MMRCFG0_R5SS1_LBIST_SPARE1 — Spare LBIST control bits
  [31:0] R5SS1_LBIST_SPARE1_SPARE1 — LBIST spare bits Reset Source: mod_g_rst_n
0xC038 MAIN_CTRL_MMRCFG0_R5SS1_LBIST_STAT access per field — Indicates LBIST status and provides MISR selection control
  [31] R5SS1_LBIST_STAT_BIST_DONE ro — LBIST is done Reset Source: mod_g_rst_n
  [15] R5SS1_LBIST_STAT_BIST_RUNNING ro — LBIST is running Reset Source: mod_g_rst_n
  [9:8] R5SS1_LBIST_STAT_OUT_MUX_CTL rw — Selects source of LBIST output 00 - LBIST IP PID value 01 - LBIST CTRL ID value 1x - MISR value Reset Source: mod_g_rst_n
  [7:0] R5SS1_LBIST_STAT_MISR_MUX_CTL rw — Selects block of 32 MISR bits to read. A value of 0 selects a compacted 32-bit version of the full MISR. A value of 1-32 select a 32-bit segment of the MISR. Reset Source: mod_g_rst_n
0xC03C MAIN_CTRL_MMRCFG0_R5SS1_LBIST_MISR ro — Contains LBIST MISR output value
  [31:0] R5SS1_LBIST_MISR_MISR_RESULT — 32-bits of MISR value selected by misr_mux_ctl Reset Source: mod_g_rst_n
0xC280 MAIN_CTRL_MMRCFG0_R5SS0_LBIST_SIG access not given reset not defined — Contains expected MISR output value
0xC2A0 MAIN_CTRL_MMRCFG0_R5SS1_LBIST_SIG access not given reset not defined — Contains expected MISR output value
0xD114 MAIN_CTRL_MMRCFG0_CLAIMREG_P3_R5_READONLY ro
  [31:0] CLAIMREG_P3_R5_READONLY — Claim bits for Partition 3 Reset Source: mod_g_rst_n
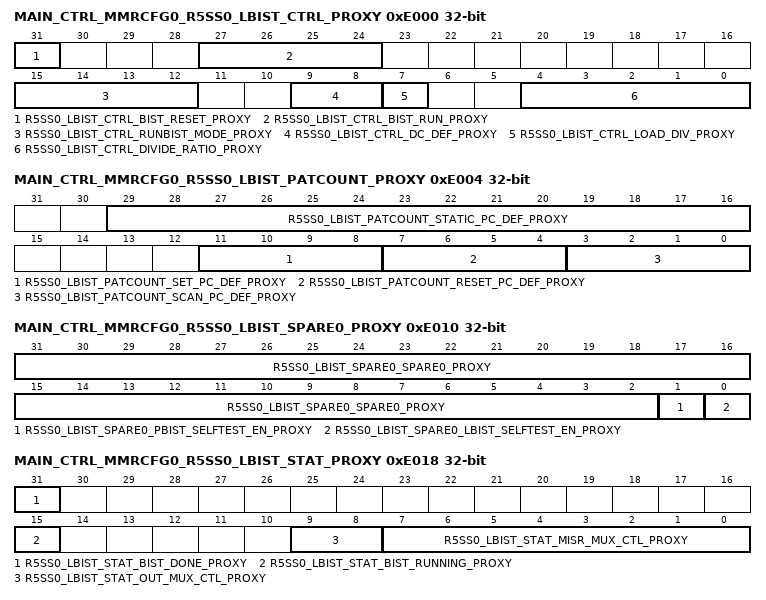
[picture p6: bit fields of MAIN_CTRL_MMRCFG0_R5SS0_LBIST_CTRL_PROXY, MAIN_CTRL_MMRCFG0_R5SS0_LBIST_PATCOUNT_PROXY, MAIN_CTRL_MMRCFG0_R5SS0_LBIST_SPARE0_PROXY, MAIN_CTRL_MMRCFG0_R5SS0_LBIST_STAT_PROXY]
0xE000 MAIN_CTRL_MMRCFG0_R5SS0_LBIST_CTRL_PROXY — Configures and enables LBIST operation
  [31] R5SS0_LBIST_CTRL_BIST_RESET_PROXY — Reset LBIST macro Reset Source: mod_g_rst_n
  [27:24] R5SS0_LBIST_CTRL_BIST_RUN_PROXY — Starts LBIST if all bits are 1 Reset Source: mod_g_rst_n
  [15:12] R5SS0_LBIST_CTRL_RUNBIST_MODE_PROXY — Runbist mode enable if all bits are 1 Reset Source: mod_g_rst_n
  [9:8] R5SS0_LBIST_CTRL_DC_DEF_PROXY — Clock delay after scan_enable switching Reset Source: mod_g_rst_n
  [7] R5SS0_LBIST_CTRL_LOAD_DIV_PROXY — Loads LBIST clock divide ratio on transition from 0 to 1 Reset Source: mod_g_rst_n
  [4:0] R5SS0_LBIST_CTRL_DIVIDE_RATIO_PROXY — LBIST clock divide ratio Reset Source: mod_g_rst_n
0xE004 MAIN_CTRL_MMRCFG0_R5SS0_LBIST_PATCOUNT_PROXY — Specifies the number of LBIST patterns to run
  [29:16] R5SS0_LBIST_PATCOUNT_STATIC_PC_DEF_PROXY — Number of stuck-at patterns to run Reset Source: mod_g_rst_n
  [11:8] R5SS0_LBIST_PATCOUNT_SET_PC_DEF_PROXY — Number of set patterns to run Reset Source: mod_g_rst_n
  [7:4] R5SS0_LBIST_PATCOUNT_RESET_PC_DEF_PROXY — Number of reset patterns to run Reset Source: mod_g_rst_n
  [3:0] R5SS0_LBIST_PATCOUNT_SCAN_PC_DEF_PROXY — Number of chain test patterns to run Reset Source: mod_g_rst_n
0xE008 MAIN_CTRL_MMRCFG0_R5SS0_LBIST_SEED0_PROXY — Specifies the 32 LSBs of the PRPG seed
  [31:0] R5SS0_LBIST_SEED0_PRPG_DEF_PROXY — Initial seed for PRPG (bits 31:0) Reset Source: mod_g_rst_n
0xE00C MAIN_CTRL_MMRCFG0_R5SS0_LBIST_SEED1_PROXY — Specifies the 21 MSBs of the PRPG seed
  [20:0] R5SS0_LBIST_SEED1_PRPG_DEF_PROXY — Initial seed for PRPG (bits 52:32) Reset Source: mod_g_rst_n
0xE010 MAIN_CTRL_MMRCFG0_R5SS0_LBIST_SPARE0_PROXY — Spare LBIST control bits
  [31:2] R5SS0_LBIST_SPARE0_SPARE0_PROXY — LBIST spare bits Reset Source: mod_g_rst_n
  [1] R5SS0_LBIST_SPARE0_PBIST_SELFTEST_EN_PROXY — PBIST isolation control Reset Source: mod_g_rst_n
  [0] R5SS0_LBIST_SPARE0_LBIST_SELFTEST_EN_PROXY — LBIST isolation control Reset Source: mod_g_rst_n
0xE014 MAIN_CTRL_MMRCFG0_R5SS0_LBIST_SPARE1_PROXY — Spare LBIST control bits
  [31:0] R5SS0_LBIST_SPARE1_SPARE1_PROXY — LBIST spare bits Reset Source: mod_g_rst_n
0xE018 MAIN_CTRL_MMRCFG0_R5SS0_LBIST_STAT_PROXY access per field — Indicates LBIST status and provides MISR selection control
  [31] R5SS0_LBIST_STAT_BIST_DONE_PROXY ro — LBIST is done Reset Source: mod_g_rst_n
  [15] R5SS0_LBIST_STAT_BIST_RUNNING_PROXY ro — LBIST is running Reset Source: mod_g_rst_n
  [9:8] R5SS0_LBIST_STAT_OUT_MUX_CTL_PROXY rw — Selects source of LBIST output 00 - LBIST IP PID value 01 - LBIST CTRL ID value 1x - MISR value Reset Source: mod_g_rst_n
  [7:0] R5SS0_LBIST_STAT_MISR_MUX_CTL_PROXY rw — Selects block of 32 MISR bits to read. A value of 0 selects a compacted 32-bit version of the full MISR. A value of 1-32 select a 32-bit segment of the MISR. Reset Source: mod_g_rst_n
0xE01C MAIN_CTRL_MMRCFG0_R5SS0_LBIST_MISR_PROXY ro — Contains LBIST MISR output value
  [31:0] R5SS0_LBIST_MISR_MISR_RESULT_PROXY — 32-bits of MISR value selected by misr_mux_ctl Reset Source: mod_g_rst_n
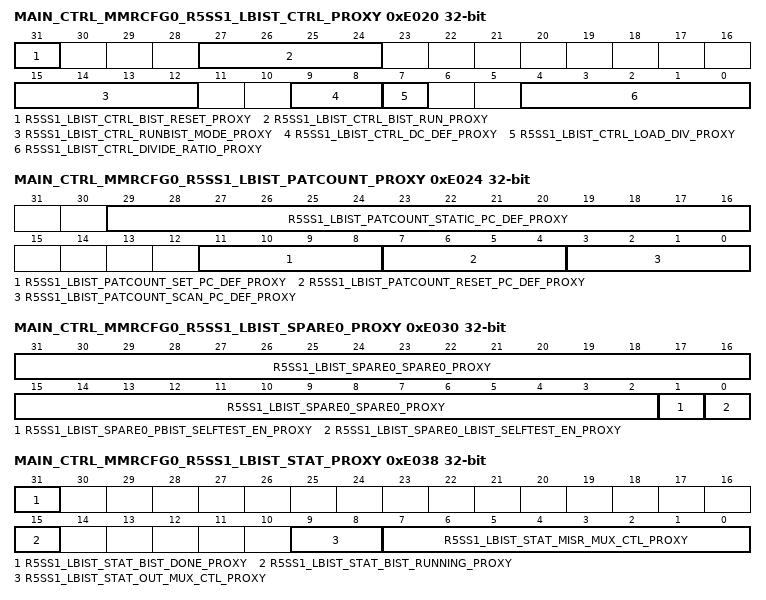
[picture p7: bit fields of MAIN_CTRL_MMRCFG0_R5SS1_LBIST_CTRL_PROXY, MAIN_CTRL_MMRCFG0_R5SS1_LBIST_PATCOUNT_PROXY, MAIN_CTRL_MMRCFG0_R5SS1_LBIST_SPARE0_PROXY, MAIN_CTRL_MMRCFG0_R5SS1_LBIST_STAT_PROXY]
0xE020 MAIN_CTRL_MMRCFG0_R5SS1_LBIST_CTRL_PROXY — Configures and enables LBIST operation
  [31] R5SS1_LBIST_CTRL_BIST_RESET_PROXY — Reset LBIST macro Reset Source: mod_g_rst_n
  [27:24] R5SS1_LBIST_CTRL_BIST_RUN_PROXY — Starts LBIST if all bits are 1 Reset Source: mod_g_rst_n
  [15:12] R5SS1_LBIST_CTRL_RUNBIST_MODE_PROXY — Runbist mode enable if all bits are 1 Reset Source: mod_g_rst_n
  [9:8] R5SS1_LBIST_CTRL_DC_DEF_PROXY — Clock delay after scan_enable switching Reset Source: mod_g_rst_n
  [7] R5SS1_LBIST_CTRL_LOAD_DIV_PROXY — Loads LBIST clock divide ratio on transition from 0 to 1 Reset Source: mod_g_rst_n
  [4:0] R5SS1_LBIST_CTRL_DIVIDE_RATIO_PROXY — LBIST clock divide ratio Reset Source: mod_g_rst_n
0xE024 MAIN_CTRL_MMRCFG0_R5SS1_LBIST_PATCOUNT_PROXY — Specifies the number of LBIST patterns to run
  [29:16] R5SS1_LBIST_PATCOUNT_STATIC_PC_DEF_PROXY — Number of stuck-at patterns to run Reset Source: mod_g_rst_n
  [11:8] R5SS1_LBIST_PATCOUNT_SET_PC_DEF_PROXY — Number of set patterns to run Reset Source: mod_g_rst_n
  [7:4] R5SS1_LBIST_PATCOUNT_RESET_PC_DEF_PROXY — Number of reset patterns to run Reset Source: mod_g_rst_n
  [3:0] R5SS1_LBIST_PATCOUNT_SCAN_PC_DEF_PROXY — Number of chain test patterns to run Reset Source: mod_g_rst_n
0xE028 MAIN_CTRL_MMRCFG0_R5SS1_LBIST_SEED0_PROXY — Specifies the 32 LSBs of the PRPG seed
  [31:0] R5SS1_LBIST_SEED0_PRPG_DEF_PROXY — Initial seed for PRPG (bits 31:0) Reset Source: mod_g_rst_n
0xE02C MAIN_CTRL_MMRCFG0_R5SS1_LBIST_SEED1_PROXY — Specifies the 21 MSBs of the PRPG seed
  [20:0] R5SS1_LBIST_SEED1_PRPG_DEF_PROXY — Initial seed for PRPG (bits 52:32) Reset Source: mod_g_rst_n
0xE030 MAIN_CTRL_MMRCFG0_R5SS1_LBIST_SPARE0_PROXY — Spare LBIST control bits
  [31:2] R5SS1_LBIST_SPARE0_SPARE0_PROXY — LBIST spare bits Reset Source: mod_g_rst_n
  [1] R5SS1_LBIST_SPARE0_PBIST_SELFTEST_EN_PROXY — PBIST isolation control Reset Source: mod_g_rst_n
  [0] R5SS1_LBIST_SPARE0_LBIST_SELFTEST_EN_PROXY — LBIST isolation control Reset Source: mod_g_rst_n
0xE034 MAIN_CTRL_MMRCFG0_R5SS1_LBIST_SPARE1_PROXY — Spare LBIST control bits
  [31:0] R5SS1_LBIST_SPARE1_SPARE1_PROXY — LBIST spare bits Reset Source: mod_g_rst_n
0xE038 MAIN_CTRL_MMRCFG0_R5SS1_LBIST_STAT_PROXY access per field — Indicates LBIST status and provides MISR selection control
  [31] R5SS1_LBIST_STAT_BIST_DONE_PROXY ro — LBIST is done Reset Source: mod_g_rst_n
  [15] R5SS1_LBIST_STAT_BIST_RUNNING_PROXY ro — LBIST is running Reset Source: mod_g_rst_n
  [9:8] R5SS1_LBIST_STAT_OUT_MUX_CTL_PROXY rw — Selects source of LBIST output 00 - LBIST IP PID value 01 - LBIST CTRL ID value 1x - MISR value Reset Source: mod_g_rst_n
  [7:0] R5SS1_LBIST_STAT_MISR_MUX_CTL_PROXY rw — Selects block of 32 MISR bits to read. A value of 0 selects a compacted 32-bit version of the full MISR. A value of 1-32 select a 32-bit segment of the MISR. Reset Source: mod_g_rst_n
0xE03C MAIN_CTRL_MMRCFG0_R5SS1_LBIST_MISR_PROXY ro — Contains LBIST MISR output value
  [31:0] R5SS1_LBIST_MISR_MISR_RESULT_PROXY — 32-bits of MISR value selected by misr_mux_ctl Reset Source: mod_g_rst_n
0xE280 MAIN_CTRL_MMRCFG0_R5SS0_LBIST_SIG_PROXY access not given reset not defined — Contains expected MISR output value
0xE2A0 MAIN_CTRL_MMRCFG0_R5SS1_LBIST_SIG_PROXY access not given reset not defined — Contains expected MISR output value
{0xF100+4i} MAIN_CTRL_MMRCFG0_CLAIMREG_P3_R{i} (i=0..5)
  [31:0] CLAIMREG_P3_R{i} — Claim bits for Partition 3 Reset Source: mod_g_rst_n
0x11128 MAIN_CTRL_MMRCFG0_CLAIMREG_P4_R10_READONLY ro
  [31:0] CLAIMREG_P4_R10_READONLY — Claim bits for Partition 4 Reset Source: mod_g_rst_n
0x11138 MAIN_CTRL_MMRCFG0_CLAIMREG_P4_R14_READONLY ro
  [31:0] CLAIMREG_P4_R14_READONLY — Claim bits for Partition 4 Reset Source: mod_g_rst_n
{0x13100+4i} MAIN_CTRL_MMRCFG0_CLAIMREG_P4_R{i} (i=0..14)
  [31:0] CLAIMREG_P4_R{i} — Claim bits for Partition 4 Reset Source: mod_g_rst_n
{0x1B100+4i} MAIN_CTRL_MMRCFG0_CLAIMREG_P6_R{i} (i=0..8)
  [31:0] CLAIMREG_P6_R{i} — Claim bits for Partition 6 Reset Source: mod_g_rst_n
